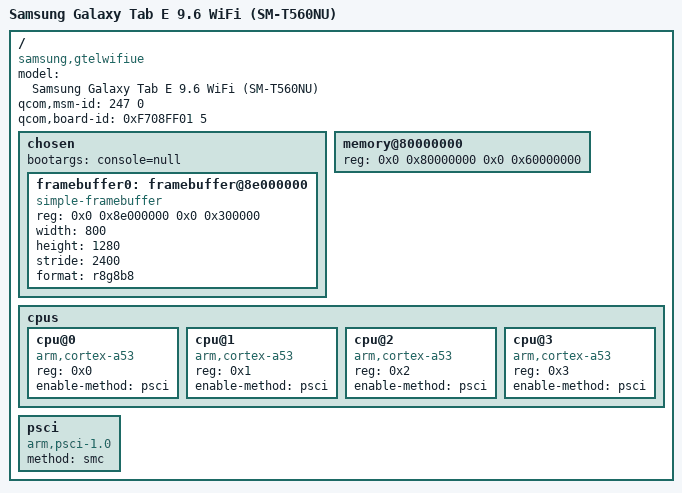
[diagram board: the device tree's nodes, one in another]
/dts-v1/;

/ {
	model = "Samsung Galaxy Tab E 9.6 WiFi (SM-T560NU)";
	compatible = "samsung,gtelwifiue", "qcom,apq8016", "qcom,msm8916";
	qcom,msm-id = <247 0>;
	qcom,board-id = <0xF708FF01 5>;

	#address-cells = <2>;
	#size-cells = <2>;

	chosen {
		bootargs = "console=null";
		#address-cells = <2>;
		#size-cells = <2>;

		framebuffer0: framebuffer@8e000000 {
			compatible = "simple-framebuffer";
			reg = <0x0 0x8e000000 0x0 0x300000>;
			width = <800>;
			height = <1280>;
			stride = <2400>;
			format = "r8g8b8";
		};
	};

	memory@80000000 {
		device_type = "memory";
		reg = <0x0 0x80000000 0x0 0x60000000>;
	};

	cpus {
		#address-cells = <1>;
		#size-cells = <0>;

		cpu@0 {
			device_type = "cpu";
			compatible = "arm,cortex-a53";
			reg = <0x0>;
			enable-method = "psci";
		};

		cpu@1 {
			device_type = "cpu";
			compatible = "arm,cortex-a53";
			reg = <0x1>;
			enable-method = "psci";
		};

		cpu@2 {
			device_type = "cpu";
			compatible = "arm,cortex-a53";
			reg = <0x2>;
			enable-method = "psci";
		};

		cpu@3 {
			device_type = "cpu";
			compatible = "arm,cortex-a53";
			reg = <0x3>;
			enable-method = "psci";
		};
	};

	psci {
		compatible = "arm,psci-1.0", "arm,psci-0.2", "arm,psci";
		method = "smc";
	};
};
